# M3351 register map
File version: 1.0
Registers are 32-bit, read-write, reset 0x0 unless marked. A register's access mark holds for its fields unless they carry their own. Offsets are from the block's base; [hi:lo] are bit positions; {n}, {i} and the like mark numbered series.

## FMC_NSBA — FMC Register Map
Base 0x5000C000
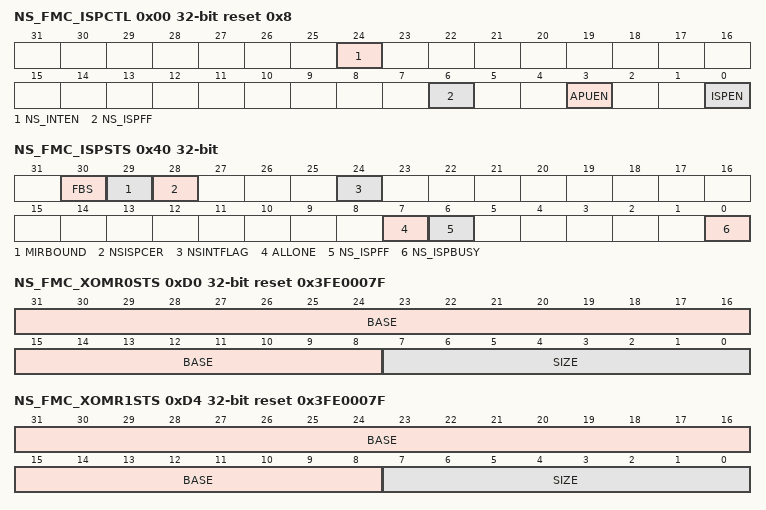
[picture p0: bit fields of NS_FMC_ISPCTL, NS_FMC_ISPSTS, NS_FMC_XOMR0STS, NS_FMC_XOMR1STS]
0x00 NS_FMC_ISPCTL reset 0x8 — Non-secure ISP Control Register
  [24] NS_INTEN — Non-secure ISP interrupt Enable Bit (Write Protect). Note: This bit is write protected. The Write Protect is effective only when both SYS_REGLCTL at SYS_BA and SYS_BA_NS are in locked state. Before using INT, user needs to clear the INTFLAG(FMC_ISPSTS[24]) make sure INT happen at correct time.
    0=NS_ISP INT Disabled; 1=NS_ISP INT Enabled
  [6] NS_ISPFF — Non-secure ISP Fail Flag (Write Protect). This bit is set by hardware when a triggered ISP meets any of the following conditions: This bit needs to be cleared by writing 1 to it. APROM writes to itself if APUEN is set to 0. Page Erase command at LOCK mode with ICE connection. Erase or Program command at brown-out detected. Destination address is illegal, such as over an available range. Invalid ISP commands. Read any content of bootloader with ICE connection. ISP CMD in XOM region, except xom page erase and chksum command. The wrong setting of page erase ISP CMD in XOM. Violate XOM setting one time protection. Page erase ISP CMD in Secure region setting page. Page erase, mass erase, 64-bit word program in OTP. NS_ISP Conflict Error. Note: This bit is write protected. Refer to the SYS_REGLCTL register.
  [3] APUEN — APROM Update Enable Bit. Note: Note: This bit is read only to show APUEN function enable.
    0=APROM cannot be updated when the chip runs in APROM; 1=APROM can be updated when the chip runs in APROM
  [0] ISPEN — ISP Enable Bit. ISP function enable. Note: This bit is read only to show ISP function enable.
    1=ISP function Enabled
0x04 NS_FMC_ISPADDR — Non-secure ISP Address Register
  [31:0] NS_ISPADDR — Non-secure ISP Address. This chip is equipped with embedded Flash. ISPADDR[1:0] must be kept 00 for ISP 32-bit operation. For CRC32 Checksum Calculation command, this field is the Flash starting address for checksum calculation, 8 Kbytes alignment is necessary for CRC32 checksum calculation. For Flash32-bit Program, ISP address needs word alignment (4-byte). For Flash 64-bit Program, ISP address needs double word alignment (8-byte). Non-secure ISP address must be active at Non-secure region.
0x08 NS_FMC_ISPDAT — Non-secure ISP Data Register
  [31:0] NS_ISPDAT — Non-secure ISP Data. Write data to this register before ISP program operation. Read data from this register after ISP read operation.
0x0C NS_FMC_ISPCMD — Non-secure ISP Command Register
  [6:0] NS_CMD — Non-secure ISP Command. ISP command table is shown below: The other commands are invalid.
    0=FLASH 32-bit Read; 4=Read Unique ID; 8=Read Flash All-One Result; 11=Read Company ID; 12=Read Device ID; 13=Read Checksum; 33=FLASH 32-bit Program; 34=FLASH Page Erase. Erase only non-secure page in two banks; 40=Run Flash All-One Verification; 45=Run Checksum Calculation; 64=FLASH 64-bit Read; 97=FLASH 64-bit Program
0x10 NS_FMC_ISPTRG — Non-secure ISP Trigger Control Register
  [0] NS_ISPGO — Non-secure ISP Start Trigger(Write Protect). Note: This bit is write protected. Refer to the SYS_REGLCTL register.
    0=ISP operation is finished; 1=ISP is progressed
0x40 NS_FMC_ISPSTS — Non-secure ISP Status Register
  [30] FBS — Flash Bank Selection (Read Only). This bit indicate which bank is selected to boot.
    0=Booting from BANK0; 1=Booting from BANK1
  [29] MIRBOUND — Mirror Boundary (Read Only)
    0=Mirror Boundary Disabled; 1=Mirror Boundary Enabled
  [28] NSISPCER — Non-secure ISP Conflict Error. This bit shows when FMC is doing ISP operation. User cannot access NS_FMC_ISP_ADDR,NS_FMC_ISPDAT,NS_FMC_ISPCMD,NS_FMC_ISPTRG. It would cause ISPFF.
  [24] NSINTFLAG — Non-secure ISP interrupt Flag. Note: This function needs to be enabled by Non-secure FMC_ISPCTRL[24].
    0=ISP Not Finished; 1=ISP done or ISPFF set
  [7] ALLONE — Flash All-one Verification Flag. This bit is set by hardware if all of Flash bits are 1, and cleared if Flash bits are not all 1 after 'Run Flash All-One Verification' is complete; this bit also can be cleared by writing 1
    0=Flash bits are not all 1 after 'Run Flash All-One Verification' complete; 1=All of Flash bits are 1 after 'Run Flash All-One Verification' complete
  [6] NS_ISPFF — Non-secure ISP Fail Flag (Write Protect). This bit is set by hardware when a triggered ISP meets any of the following conditions: This bit needs to be cleared by writing 1 to it. APROM writes to itself if APUEN is set to 0. Page Erase command at LOCK mode with ICE connection. Erase or Program command at brown-out detected. Destination address is illegal, such as over an available range. Invalid ISP commands. Read any content of bootloader with ICE connection. ISP CMD in XOM region, except XOM page erase and chksum command. The wrong setting of page erase ISP CMD in XOM. Violate XOM setting one time protection. Page erase ISP CMD in Secure region setting page. Page erase, mass erase, 64-bit word program in OTP. Note: This bit is write protected. Refer to the SYS_REGLCTL register.
  [0] NS_ISPBUSY — Non-secure ISP Busy Flag (Read Only). Write 1 to start ISP operation and this bit will be cleared to 0 by hardware automatically when ISP operation is finished. This bit is the mirror of ISPGO(FMC_ISPTRG[0]).
    0=ISP operation is finished; 1=ISP is progressed
0x80 NS_FMC_MPDAT0 — Non-secure ISP Data0 Register
  [31:0] NS_ISPDAT0 — Non-secure ISP Data 0. This register is the first 32-bit data for 32-bit/64-bit programming, and it is also the mirror of NS_FMC_ISPDAT, both registers keep the same data.
0x84 NS_FMC_MPDAT1 — Non-secure ISP Data1 Register
  [31:0] NS_ISPDAT1 — Non-secure ISP Data 1. This register is the second 32-bit read data or write data for 64-bit programming.
0x90 NS_FMC_MPDATE — Non-secure ECC Error Syndrome Register
  [7:0] NS_ISPDATE — Non-secure ECC Error Syndrome. Read data from this register after ISP 64-bit read operation or ECCSEBCF(NS_FMC_ECCSTS[0]) is high can know which bit is error. ISPDATE does not continuously store the position information of ECC errors. Therefore, if the user wants to know which bit generated the error, they need to read it before the next ISP action after an ECC single-bit error occurs, or access that position again. This register is the ECC 8-bit data.
0xD0 NS_FMC_XOMR0STS ro reset 0x3FE0007F — Non-secure XOM Region 0 Status Register
  [31:8] BASE — XOM Region 0 Base Address. BASE is the base address of XOM Region 0. Note: The base address is page aligned.
  [7:0] SIZE — XOM Region 0 Size. SIZE is the page number of XOM Region 0.
0xD4 NS_FMC_XOMR1STS ro reset 0x3FE0007F — Non-secure XOM Region 1 Status Register
  [31:8] BASE — XOM Region 1 Base Address. BASE is the base address of XOM Region 1. Note: The base address is page aligned.
  [7:0] SIZE — XOM Region 1 Size. SIZE is the page number of XOM Region 1.
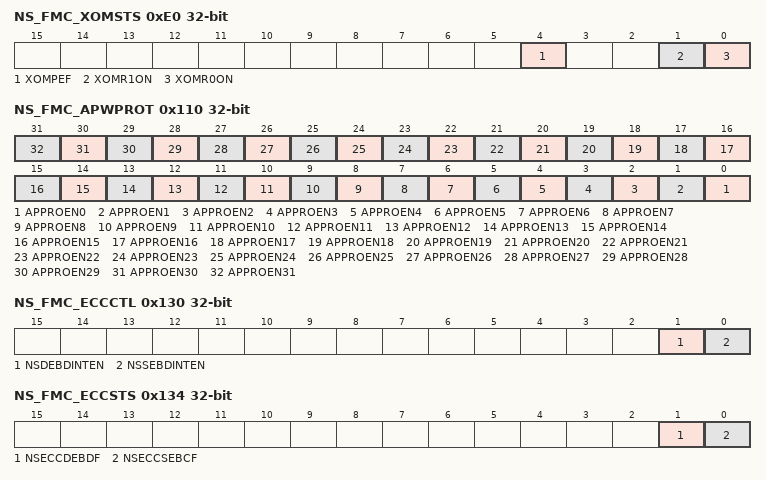
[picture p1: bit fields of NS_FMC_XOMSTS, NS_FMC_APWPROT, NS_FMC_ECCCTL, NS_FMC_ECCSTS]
0xE0 NS_FMC_XOMSTS ro — Non-secure XOM Status Register
  [4] XOMPEF — XOM Page Erase Function Fail. XOM page erase function status. If XOMPEF is set to 1, user needs to erase XOM region again.
    0=Success; 1=Fail
  [1] XOMR1ON — XOM Region 1 On. XOM Region 1 active status.
    0=Not active; 1=XOM region 1 is active
  [0] XOMR0ON — XOM Region 0 On. XOM Region 0 active status.
    0=Not active; 1=XOM region 0 is active
0x110 NS_FMC_APWPROT ro — Non-secure APROM Write Protect Register
  [all] fields
    0=APROM region n is not protected; 1=APROM region n is protected
  [n] APPROEN{n} (n=0..31) — Non-secure APROM Proect enable. This bit indicates which APROM region is protected. Note: APROM protect region is 0x1000_0000 + n*(0x8000) to 0x1000_7fff + n*(0x8000)
0x118 NS_FMC_APWPKEEP ro — Non-secure APROM Write Protect Keep Register
  [15:0] APWPKEEP0 — Non-secure APROM Write Protect Keep 0 (Write Protect)
    0x55AA=APWPROT register is be locked
0x11C NS_FMC_SCACT ro — Non-secure APROM Secure Conceal Active Register
  [0] SCACT — Non-Secure AOROM Secure Conceal Function Active. Note: secure conceal function active will base on this bit and setting of CONFIG6 is all 0.
    0=secure conceal function inactive; 1=secure conceal function active
0x130 NS_FMC_ECCCTL — Non-secure Error Code Correction Control
  [1] NSDEBDINTEN — Non-secure Double Error Bits Detection Interrupt Enable (Write Protect). Note: This bit is write protected. Refer to the SYS_REGLCTL register.
    0=Double Error Bits Detection Interruput Disabled; 1=Double Error Bits Detection Interruput Enabled
  [0] NSSEBDINTEN — Non-secure Single Error Bits Detection Interrupt Enable (Write Protect). Note: This bit is write protected. Refer to the SYS_REGLCTL register.
    0=Single Error Bit Detection Interruput Disabled; 1=Single Error Bit Detection Interruput Enabled
0x134 NS_FMC_ECCSTS — Non-secure Error Code Correction Status
  [1] NSECCDEBDF — Non-secure ECC Double Error Bits Detection Flag
    0=FMC does not detect ECC double error bits fault; 1=FMC detects ECC double error bits fault
  [0] NSECCSEBCF — Non-secure ECC Single Error Bits Correction Flag
    0=FMC does not detect ECC single error bits fault; 1=FMC detects and corrects ECC single error bits fault
0x138 NS_FMC_ECCSEFAR ro — Non-secure ECC Single Error Fault Address Register
  [31:0] NSECCSEFAR — Non Secure ECC Single Error Fault Address Register (Read Only). When FMC detects a NSECCSEBCF(NS_FMC_ECCSTS[0]) would record fault address at the register. The register is cleared by writing 1 to NSECCSEBCF. NSECCSEFAR is 64-bit alignment so NSECCSEFAR[2:0] are always 0.
0x13C NS_FMC_ECCDEFAR ro — Non-secure ECC Double Error Fault Address Register
  [31:0] NSECCDEFAR — Non Secure ECC Double Error Fault Address Register (Read Only). When FMC detects a NSECCDEBDF(NS_FMC_ECCSTS[1]) would record fault address at the register. The register is cleared by writing 1 to NSECCDEBDF. NSECCDEBDF is 64-bit alignment so NSECCDEFAR[2:0] are always 0.
